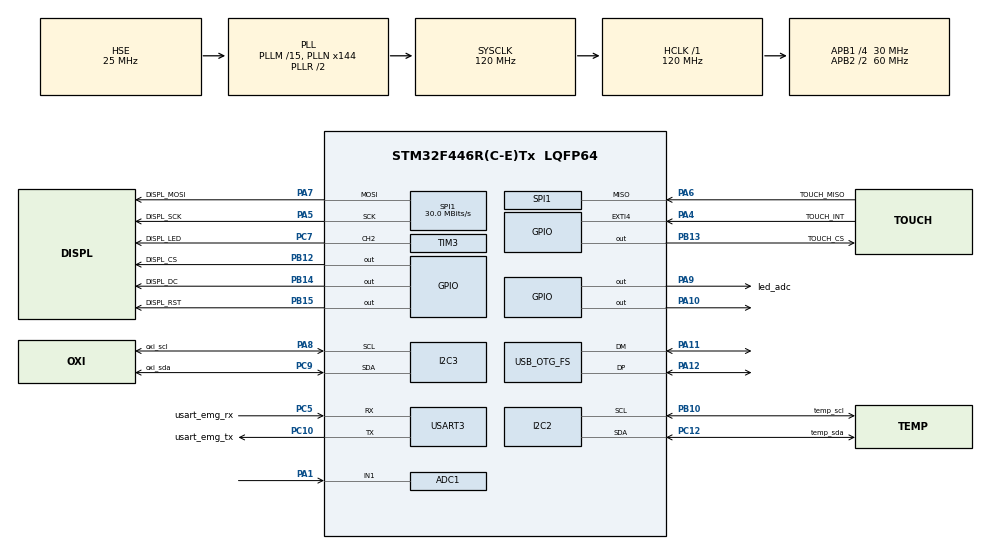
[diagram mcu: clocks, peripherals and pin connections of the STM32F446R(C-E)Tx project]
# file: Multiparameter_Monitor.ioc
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ADC1.Channel-7\#ChannelRegularConversion=ADC_CHANNEL_1
ADC1.ContinuousConvMode=ENABLE
ADC1.DMAContinuousRequests=ENABLE
ADC1.NbrOfConversionFlag=1
ADC1.Rank-7\#ChannelRegularConversion=1
ADC1.SamplingTime-7\#ChannelRegularConversion=ADC_SAMPLETIME_3CYCLES
ADC1.master=1
Dma.ADC1.1.Direction=DMA_PERIPH_TO_MEMORY
Dma.ADC1.1.FIFOMode=DMA_FIFOMODE_DISABLE
Dma.ADC1.1.Instance=DMA2_Stream0
Dma.ADC1.1.MemDataAlignment=DMA_MDATAALIGN_HALFWORD
Dma.ADC1.1.MemInc=DMA_MINC_ENABLE
Dma.ADC1.1.Mode=DMA_CIRCULAR
Dma.ADC1.1.PeriphDataAlignment=DMA_PDATAALIGN_HALFWORD
Dma.ADC1.1.PeriphInc=DMA_PINC_DISABLE
Dma.ADC1.1.Priority=DMA_PRIORITY_LOW
Dma.Request0=SPI1_TX
Dma.Request1=ADC1
Dma.SPI1_TX.0.Direction=DMA_MEMORY_TO_PERIPH
Dma.SPI1_TX.0.FIFOMode=DMA_FIFOMODE_DISABLE
Dma.SPI1_TX.0.Instance=DMA2_Stream3
Dma.SPI1_TX.0.MemDataAlignment=DMA_MDATAALIGN_BYTE
Dma.SPI1_TX.0.MemInc=DMA_MINC_ENABLE
Dma.SPI1_TX.0.Mode=DMA_NORMAL
Dma.SPI1_TX.0.PeriphDataAlignment=DMA_PDATAALIGN_BYTE
Dma.SPI1_TX.0.PeriphInc=DMA_PINC_DISABLE
Dma.SPI1_TX.0.Priority=DMA_PRIORITY_LOW
Mcu.Family=STM32F4
Mcu.Name=STM32F446R(C-E)Tx
Mcu.Package=LQFP64
NVIC.DMA2_Stream0_IRQn=true\:0\:0\:false\:false\:true\:false\:true\:true
NVIC.DMA2_Stream3_IRQn=true\:0\:0\:false\:false\:true\:false\:true\:true
NVIC.PriorityGroup=NVIC_PRIORITYGROUP_4
NVIC.SPI1_IRQn=true\:0\:0\:false\:false\:true\:true\:true\:true
NVIC.TIM1_UP_TIM10_IRQn=true\:15\:0\:false\:false\:true\:false\:true\:true
NVIC.TimeBase=TIM1_UP_TIM10_IRQn
NVIC.TimeBaseIP=TIM1
PA1.GPIO_Mode=GPIO_MODE_ANALOG
PA1.GPIO_PuPd=GPIO_NOPULL
PA1.Signal=ADCx_IN1
PA10.Signal=GPIO_Output
PA11.Mode=Device_Only
PA11.Signal=USB_OTG_FS_DM
PA12.Mode=Device_Only
PA12.Signal=USB_OTG_FS_DP
PA13.Mode=Serial_Wire
PA13.Signal=SYS_JTMS-SWDIO
PA14.Mode=Serial_Wire
PA14.Signal=SYS_JTCK-SWCLK
PA4.GPIO_Label=TOUCH_INT
PA4.GPIO_ModeDefaultEXTI=GPIO_MODE_IT_FALLING
PA4.GPIO_PuPd=GPIO_PULLUP
PA4.Signal=GPXTI4
PA5.GPIO_Label=DISPL_SCK
PA5.Mode=Full_Duplex_Master
PA5.Signal=SPI1_SCK
PA6.GPIO_Label=TOUCH_MISO
PA6.Mode=Full_Duplex_Master
PA6.Signal=SPI1_MISO
PA7.GPIO_Label=DISPL_MOSI
PA7.Mode=Full_Duplex_Master
PA7.Signal=SPI1_MOSI
PA8.GPIO_Label=oxi_scl
PA8.Mode=I2C
PA8.Signal=I2C3_SCL
PA9.GPIO_Label=led_adc
PA9.Signal=GPIO_Output
PB10.GPIO_Label=temp_scl
PB10.Mode=I2C
PB10.Signal=I2C2_SCL
PB12.GPIO_Label=DISPL_CS
PB12.GPIO_Speed=GPIO_SPEED_FREQ_HIGH
PB12.PinState=GPIO_PIN_SET
PB12.Signal=GPIO_Output
PB13.GPIO_Label=TOUCH_CS
PB13.GPIO_Speed=GPIO_SPEED_FREQ_HIGH
PB13.PinState=GPIO_PIN_SET
PB13.Signal=GPIO_Output
PB14.GPIO_Label=DISPL_DC
PB14.GPIO_Speed=GPIO_SPEED_FREQ_HIGH
PB14.PinState=GPIO_PIN_SET
PB14.Signal=GPIO_Output
PB15.GPIO_Label=DISPL_RST
PB15.Signal=GPIO_Output
PC10.GPIO_Label=usart_emg_tx
PC10.Mode=Asynchronous
PC10.Signal=USART3_TX
PC12.GPIO_Label=temp_sda
PC12.Mode=I2C
PC12.Signal=I2C2_SDA
PC5.GPIO_Label=usart_emg_rx
PC5.Mode=Asynchronous
PC5.Signal=USART3_RX
PC7.GPIO_Label=DISPL_LED
PC7.Signal=S_TIM3_CH2
PC9.GPIO_Label=oxi_sda
PC9.Mode=I2C
PC9.Signal=I2C3_SDA
PH0-OSC_IN.Mode=HSE-External-Oscillator
PH0-OSC_IN.Signal=RCC_OSC_IN
PH1-OSC_OUT.Mode=HSE-External-Oscillator
PH1-OSC_OUT.Signal=RCC_OSC_OUT
ProjectManager.HeapSize=0x200
ProjectManager.StackSize=0x400
ProjectManager.TargetToolchain=STM32CubeIDE
RCC.AHBFreq_Value=120000000
RCC.APB1CLKDivider=RCC_HCLK_DIV4
RCC.APB1Freq_Value=30000000
RCC.APB1TimFreq_Value=60000000
RCC.APB2CLKDivider=RCC_HCLK_DIV2
RCC.APB2Freq_Value=60000000
RCC.APB2TimFreq_Value=120000000
RCC.CortexFreq_Value=120000000
RCC.HCLKFreq_Value=120000000
RCC.HSE_VALUE=25000000
RCC.PLLM=15
RCC.PLLN=144
RCC.PLLQ=5
RCC.SYSCLKFreq_VALUE=120000000
RCC.SYSCLKSource=RCC_SYSCLKSOURCE_PLLRCLK
RCC.USBFreq_Value=48000000
RCC.VCOOutputFreq_Value=240000000
SH.ADCx_IN1.0=ADC1_IN1,IN1
SH.S_TIM3_CH2.0=TIM3_CH2,PWM Generation2 CH2
SPI1.CalculateBaudRate=30.0 MBits/s
SPI1.Direction=SPI_DIRECTION_2LINES
SPI1.Mode=SPI_MODE_MASTER
SPI1.VirtualType=VM_MASTER
STMicroelectronics.X-CUBE-TOUCHGFX.4.22.1.ApplicationCcGraphicsJjApplication=TouchGFXOoGenerator
STMicroelectronics.X-CUBE-TOUCHGFX.4.22.1.tgfx_buffering_strategy=Partial
STMicroelectronics.X-CUBE-TOUCHGFX.4.22.1.tgfx_custom_height=480
STMicroelectronics.X-CUBE-TOUCHGFX.4.22.1.tgfx_custom_width=320
STMicroelectronics.X-CUBE-TOUCHGFX.4.22.1.tgfx_pixel_format=RGB565\:16
STMicroelectronics.X-CUBE-TOUCHGFX.4.22.1_IsPackSelfContextualization=true
TIM3.Channel-PWM\ Generation2\ CH2=TIM_CHANNEL_2
TIM3.Period=100
TIM3.Pulse-PWM\ Generation2\ CH2=2499
USART3.VirtualMode=VM_ASYNC
USB_OTG_FS.VirtualMode=Device_Only
VP_CRC_VS_CRC.Mode=CRC_Activate
VP_STMicroelectronics.X-CUBE-TOUCHGFX_VS_GraphicsJjApplication_4.22.1.Mode=GraphicsJjApplication
VP_SYS_VS_tim1.Mode=TIM1
board=custom

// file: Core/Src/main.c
/* USER CODE BEGIN Header */
/**
  ******************************************************************************
  * @file           : main.c
  * @brief          : Main program body
  ******************************************************************************
  * @attention
  *
  * Copyright (c) 2023 STMicroelectronics.
  * All rights reserved.
  *
  * This software is licensed under terms that can be found in the LICENSE file
  * in the root directory of this software component.
  * If no LICENSE file comes with this software, it is provided AS-IS.
  *
  ******************************************************************************
  */
/* USER CODE END Header */
#include "main.h"

/* USER CODE BEGIN Includes */
#include "myheaders.h"
/* USER CODE END Includes */

ADC_HandleTypeDef hadc1;
DMA_HandleTypeDef hdma_adc1;

CRC_HandleTypeDef hcrc;

I2C_HandleTypeDef hi2c2;
I2C_HandleTypeDef hi2c3;

SPI_HandleTypeDef hspi1;
DMA_HandleTypeDef hdma_spi1_tx;

TIM_HandleTypeDef htim3;

UART_HandleTypeDef huart3;

PCD_HandleTypeDef hpcd_USB_OTG_FS;

void SystemClock_Config(void);
static void MX_GPIO_Init(void);
static void MX_DMA_Init(void);
static void MX_USB_OTG_FS_PCD_Init(void);
static void MX_ADC1_Init(void);
static void MX_I2C3_Init(void);
static void MX_I2C2_Init(void);
static void MX_SPI1_Init(void);
static void MX_CRC_Init(void);
static void MX_TIM3_Init(void);
static void MX_USART3_UART_Init(void);

int main(void)
{

  /* MCU Configuration--------------------------------------------------------*/

  /* Reset of all peripherals, Initializes the Flash interface and the Systick. */
  HAL_Init();

  /* Configure the system clock */
  SystemClock_Config();

  /* Initialize all configured peripherals */
  MX_GPIO_Init();
  MX_DMA_Init();
  MX_USB_OTG_FS_PCD_Init();
  MX_ADC1_Init();
  MX_I2C3_Init();
  MX_I2C2_Init();
  MX_SPI1_Init();
  MX_CRC_Init();
  MX_TIM3_Init();
  MX_USART3_UART_Init();

  /* Infinite loop */
  while (1)
  {
  }
}

void SystemClock_Config(void)
{
  RCC_OscInitTypeDef RCC_OscInitStruct = {0};
  RCC_ClkInitTypeDef RCC_ClkInitStruct = {0};

  /** Configure the main internal regulator output voltage
  */
  __HAL_RCC_PWR_CLK_ENABLE();
  __HAL_PWR_VOLTAGESCALING_CONFIG(PWR_REGULATOR_VOLTAGE_SCALE3);

  /** Initializes the RCC Oscillators according to the specified parameters
  * in the RCC_OscInitTypeDef structure.
  */
  RCC_OscInitStruct.OscillatorType = RCC_OSCILLATORTYPE_HSE;
  RCC_OscInitStruct.HSEState = RCC_HSE_ON;
  RCC_OscInitStruct.PLL.PLLState = RCC_PLL_ON;
  RCC_OscInitStruct.PLL.PLLSource = RCC_PLLSOURCE_HSE;
  RCC_OscInitStruct.PLL.PLLM = 15;
  RCC_OscInitStruct.PLL.PLLN = 144;
  RCC_OscInitStruct.PLL.PLLP = RCC_PLLP_DIV2;
  RCC_OscInitStruct.PLL.PLLQ = 5;
  RCC_OscInitStruct.PLL.PLLR = 2;
  if (HAL_RCC_OscConfig(&RCC_OscInitStruct) != HAL_OK)
  {
    Error_Handler();
  }

  /** Initializes the CPU, AHB and APB buses clocks
  */
  RCC_ClkInitStruct.ClockType = RCC_CLOCKTYPE_HCLK|RCC_CLOCKTYPE_SYSCLK
                              |RCC_CLOCKTYPE_PCLK1|RCC_CLOCKTYPE_PCLK2;
  RCC_ClkInitStruct.SYSCLKSource = RCC_SYSCLKSOURCE_PLLRCLK;
  RCC_ClkInitStruct.AHBCLKDivider = RCC_SYSCLK_DIV1;
  RCC_ClkInitStruct.APB1CLKDivider = RCC_HCLK_DIV4;
  RCC_ClkInitStruct.APB2CLKDivider = RCC_HCLK_DIV2;

  if (HAL_RCC_ClockConfig(&RCC_ClkInitStruct, FLASH_LATENCY_3) != HAL_OK)
  {
    Error_Handler();
  }
}

static void MX_ADC1_Init(void)
{

  ADC_ChannelConfTypeDef sConfig = {0};

  /** Configure the global features of the ADC (Clock, Resolution, Data Alignment and number of conversion)
  */
  hadc1.Instance = ADC1;
  hadc1.Init.ClockPrescaler = ADC_CLOCK_SYNC_PCLK_DIV2;
  hadc1.Init.Resolution = ADC_RESOLUTION_12B;
  hadc1.Init.ScanConvMode = DISABLE;
  hadc1.Init.ContinuousConvMode = ENABLE;
  hadc1.Init.DiscontinuousConvMode = DISABLE;
  hadc1.Init.ExternalTrigConvEdge = ADC_EXTERNALTRIGCONVEDGE_NONE;
  hadc1.Init.ExternalTrigConv = ADC_SOFTWARE_START;
  hadc1.Init.DataAlign = ADC_DATAALIGN_RIGHT;
  hadc1.Init.NbrOfConversion = 1;
  hadc1.Init.DMAContinuousRequests = ENABLE;
  hadc1.Init.EOCSelection = ADC_EOC_SINGLE_CONV;
  if (HAL_ADC_Init(&hadc1) != HAL_OK)
  {
    Error_Handler();
  }

  /** Configure for the selected ADC regular channel its corresponding rank in the sequencer and its sample time.
  */
  sConfig.Channel = ADC_CHANNEL_1;
  sConfig.Rank = 1;
  sConfig.SamplingTime = ADC_SAMPLETIME_3CYCLES;
  if (HAL_ADC_ConfigChannel(&hadc1, &sConfig) != HAL_OK)
  {
    Error_Handler();
  }

}

static void MX_CRC_Init(void)
{

  hcrc.Instance = CRC;
  if (HAL_CRC_Init(&hcrc) != HAL_OK)
  {
    Error_Handler();
  }

}

static void MX_I2C2_Init(void)
{

  hi2c2.Instance = I2C2;
  hi2c2.Init.ClockSpeed = 100000;
  hi2c2.Init.DutyCycle = I2C_DUTYCYCLE_2;
  hi2c2.Init.OwnAddress1 = 0;
  hi2c2.Init.AddressingMode = I2C_ADDRESSINGMODE_7BIT;
  hi2c2.Init.DualAddressMode = I2C_DUALADDRESS_DISABLE;
  hi2c2.Init.OwnAddress2 = 0;
  hi2c2.Init.GeneralCallMode = I2C_GENERALCALL_DISABLE;
  hi2c2.Init.NoStretchMode = I2C_NOSTRETCH_DISABLE;
  if (HAL_I2C_Init(&hi2c2) != HAL_OK)
  {
    Error_Handler();
  }

}

static void MX_I2C3_Init(void)
{

  hi2c3.Instance = I2C3;
  hi2c3.Init.ClockSpeed = 100000;
  hi2c3.Init.DutyCycle = I2C_DUTYCYCLE_2;
  hi2c3.Init.OwnAddress1 = 0;
  hi2c3.Init.AddressingMode = I2C_ADDRESSINGMODE_7BIT;
  hi2c3.Init.DualAddressMode = I2C_DUALADDRESS_DISABLE;
  hi2c3.Init.OwnAddress2 = 0;
  hi2c3.Init.GeneralCallMode = I2C_GENERALCALL_DISABLE;
  hi2c3.Init.NoStretchMode = I2C_NOSTRETCH_DISABLE;
  if (HAL_I2C_Init(&hi2c3) != HAL_OK)
  {
    Error_Handler();
  }

}

static void MX_SPI1_Init(void)
{

  /* SPI1 parameter configuration*/
  hspi1.Instance = SPI1;
  hspi1.Init.Mode = SPI_MODE_MASTER;
  hspi1.Init.Direction = SPI_DIRECTION_2LINES;
  hspi1.Init.DataSize = SPI_DATASIZE_8BIT;
  hspi1.Init.CLKPolarity = SPI_POLARITY_LOW;
  hspi1.Init.CLKPhase = SPI_PHASE_1EDGE;
  hspi1.Init.NSS = SPI_NSS_SOFT;
  hspi1.Init.BaudRatePrescaler = SPI_BAUDRATEPRESCALER_2;
  hspi1.Init.FirstBit = SPI_FIRSTBIT_MSB;
  hspi1.Init.TIMode = SPI_TIMODE_DISABLE;
  hspi1.Init.CRCCalculation = SPI_CRCCALCULATION_DISABLE;
  hspi1.Init.CRCPolynomial = 10;
  if (HAL_SPI_Init(&hspi1) != HAL_OK)
  {
    Error_Handler();
  }

}

static void MX_TIM3_Init(void)
{

  TIM_MasterConfigTypeDef sMasterConfig = {0};
  TIM_OC_InitTypeDef sConfigOC = {0};

  htim3.Instance = TIM3;
  htim3.Init.Prescaler = 0;
  htim3.Init.CounterMode = TIM_COUNTERMODE_UP;
  htim3.Init.Period = 100;
  htim3.Init.ClockDivision = TIM_CLOCKDIVISION_DIV1;
  htim3.Init.AutoReloadPreload = TIM_AUTORELOAD_PRELOAD_DISABLE;
  if (HAL_TIM_PWM_Init(&htim3) != HAL_OK)
  {
    Error_Handler();
  }
  sMasterConfig.MasterOutputTrigger = TIM_TRGO_RESET;
  sMasterConfig.MasterSlaveMode = TIM_MASTERSLAVEMODE_DISABLE;
  if (HAL_TIMEx_MasterConfigSynchronization(&htim3, &sMasterConfig) != HAL_OK)
  {
    Error_Handler();
  }
  sConfigOC.OCMode = TIM_OCMODE_PWM1;
  sConfigOC.Pulse = 2499;
  sConfigOC.OCPolarity = TIM_OCPOLARITY_HIGH;
  sConfigOC.OCFastMode = TIM_OCFAST_DISABLE;
  if (HAL_TIM_PWM_ConfigChannel(&htim3, &sConfigOC, TIM_CHANNEL_2) != HAL_OK)
  {
    Error_Handler();
  }
  HAL_TIM_MspPostInit(&htim3);

}

static void MX_USART3_UART_Init(void)
{

  huart3.Instance = USART3;
  huart3.Init.BaudRate = 115200;
  huart3.Init.WordLength = UART_WORDLENGTH_8B;
  huart3.Init.StopBits = UART_STOPBITS_1;
  huart3.Init.Parity = UART_PARITY_NONE;
  huart3.Init.Mode = UART_MODE_TX_RX;
  huart3.Init.HwFlowCtl = UART_HWCONTROL_NONE;
  huart3.Init.OverSampling = UART_OVERSAMPLING_16;
  if (HAL_UART_Init(&huart3) != HAL_OK)
  {
    Error_Handler();
  }

}

static void MX_USB_OTG_FS_PCD_Init(void)
{

  hpcd_USB_OTG_FS.Instance = USB_OTG_FS;
  hpcd_USB_OTG_FS.Init.dev_endpoints = 6;
  hpcd_USB_OTG_FS.Init.speed = PCD_SPEED_FULL;
  hpcd_USB_OTG_FS.Init.dma_enable = DISABLE;
  hpcd_USB_OTG_FS.Init.phy_itface = PCD_PHY_EMBEDDED;
  hpcd_USB_OTG_FS.Init.Sof_enable = DISABLE;
  hpcd_USB_OTG_FS.Init.low_power_enable = DISABLE;
  hpcd_USB_OTG_FS.Init.lpm_enable = DISABLE;
  hpcd_USB_OTG_FS.Init.vbus_sensing_enable = DISABLE;
  hpcd_USB_OTG_FS.Init.use_dedicated_ep1 = DISABLE;
  if (HAL_PCD_Init(&hpcd_USB_OTG_FS) != HAL_OK)
  {
    Error_Handler();
  }

}

static void MX_DMA_Init(void)
{

  /* DMA controller clock enable */
  __HAL_RCC_DMA2_CLK_ENABLE();

  /* DMA interrupt init */
  /* DMA2_Stream0_IRQn interrupt configuration */
  HAL_NVIC_SetPriority(DMA2_Stream0_IRQn, 0, 0);
  HAL_NVIC_EnableIRQ(DMA2_Stream0_IRQn);
  /* DMA2_Stream3_IRQn interrupt configuration */
  HAL_NVIC_SetPriority(DMA2_Stream3_IRQn, 0, 0);
  HAL_NVIC_EnableIRQ(DMA2_Stream3_IRQn);

}

static void MX_GPIO_Init(void)
{
  GPIO_InitTypeDef GPIO_InitStruct = {0};

  /* GPIO Ports Clock Enable */
  __HAL_RCC_GPIOH_CLK_ENABLE();
  __HAL_RCC_GPIOA_CLK_ENABLE();
  __HAL_RCC_GPIOC_CLK_ENABLE();
  __HAL_RCC_GPIOB_CLK_ENABLE();

  /*Configure GPIO pin Output Level */
  HAL_GPIO_WritePin(GPIOB, DISPL_CS_Pin|TOUCH_CS_Pin|DISPL_DC_Pin, GPIO_PIN_SET);

  /*Configure GPIO pin Output Level */
  HAL_GPIO_WritePin(DISPL_RST_GPIO_Port, DISPL_RST_Pin, GPIO_PIN_RESET);

  /*Configure GPIO pin Output Level */
  HAL_GPIO_WritePin(GPIOA, led_adc_Pin|GPIO_PIN_10, GPIO_PIN_RESET);

  /*Configure GPIO pin : TOUCH_INT_Pin */
  GPIO_InitStruct.Pin = TOUCH_INT_Pin;
  GPIO_InitStruct.Mode = GPIO_MODE_IT_FALLING;
  GPIO_InitStruct.Pull = GPIO_PULLUP;
  HAL_GPIO_Init(TOUCH_INT_GPIO_Port, &GPIO_InitStruct);

  /*Configure GPIO pins : DISPL_CS_Pin TOUCH_CS_Pin DISPL_DC_Pin */
  GPIO_InitStruct.Pin = DISPL_CS_Pin|TOUCH_CS_Pin|DISPL_DC_Pin;
  GPIO_InitStruct.Mode = GPIO_MODE_OUTPUT_PP;
  GPIO_InitStruct.Pull = GPIO_NOPULL;
  GPIO_InitStruct.Speed = GPIO_SPEED_FREQ_HIGH;
  HAL_GPIO_Init(GPIOB, &GPIO_InitStruct);

  /*Configure GPIO pin : DISPL_RST_Pin */
  GPIO_InitStruct.Pin = DISPL_RST_Pin;
  GPIO_InitStruct.Mode = GPIO_MODE_OUTPUT_PP;
  GPIO_InitStruct.Pull = GPIO_NOPULL;
  GPIO_InitStruct.Speed = GPIO_SPEED_FREQ_LOW;
  HAL_GPIO_Init(DISPL_RST_GPIO_Port, &GPIO_InitStruct);

  /*Configure GPIO pins : led_adc_Pin PA10 */
  GPIO_InitStruct.Pin = led_adc_Pin|GPIO_PIN_10;
  GPIO_InitStruct.Mode = GPIO_MODE_OUTPUT_PP;
  GPIO_InitStruct.Pull = GPIO_NOPULL;
  GPIO_InitStruct.Speed = GPIO_SPEED_FREQ_LOW;
  HAL_GPIO_Init(GPIOA, &GPIO_InitStruct);

}

void HAL_TIM_PeriodElapsedCallback(TIM_HandleTypeDef *htim)
{
  if (htim->Instance == TIM1) {
    HAL_IncTick();
  }
}

void Error_Handler(void)
{
  __disable_irq();
  while (1)
  {
  }
}
